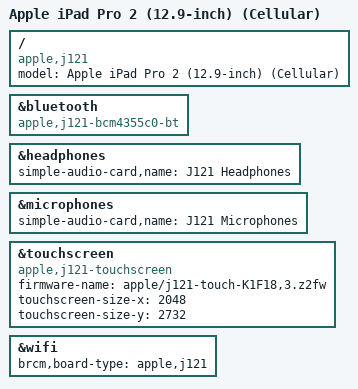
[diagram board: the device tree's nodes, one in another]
// SPDX-License-Identifier: GPL-2.0+ OR MIT
/*
 * Apple iPad Pro 2 (12.9-inch) (Cellular), J121, iPad7,2 (A1671)
 * Copyright (c) 2022, Konrad Dybcio <konradybcio@kernel.org>
 */

/dts-v1/;

#include "t8011.dtsi"
#include "t8011-common.dtsi"
#include "t8011-pro2.dtsi"

/ {
	compatible = "apple,j121", "apple,t8011", "apple,arm-platform";
	model = "Apple iPad Pro 2 (12.9-inch) (Cellular)";
};

&bluetooth {
	compatible = "apple,j121-bcm4355c0-bt", "brcm,bcm4355c0-bt";
};

&headphones {
	simple-audio-card,name = "J121 Headphones";
};

&microphones {
	simple-audio-card,name = "J121 Microphones";
};

/* Touch personality K1F18,3 (ADT multi-touch hid-merge-personality) */
&touchscreen {
	compatible = "apple,j121-touchscreen";
	firmware-name = "apple/j121-touch-K1F18,3.z2fw";
	touchscreen-size-x = <2048>;
	touchscreen-size-y = <2732>;
};

&wifi {
	brcm,board-type = "apple,j121";
};
